# MSP430FR2355 register map
Vendor: msp430gen; File version: v0.4.0-28-gb0087ce-dirty
Registers are 16-bit, read-write, reset 0x0 unless marked. A register's access mark holds for its fields unless they carry their own. Offsets are from the block's base; [hi:lo] are bit positions; {n}, {i} and the like mark numbered series; 'fields as' and 'values as' point back to an identical list.

## RTC
Base 0x00000300
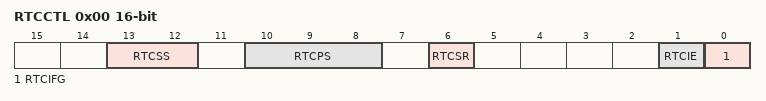
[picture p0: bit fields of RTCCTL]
0x00 RTCCTL — RTCCTL0 Register
  [13:12] RTCSS — Real-time clock source select
    0=DISABLED; 1=SMCLK; 2=XT1CLK; 3=VLOCLK
  [10:8] RTCPS — Real-time clock pre-divider select
    0=1; 1=10; 2=100; 3=1000; 4=16; 5=64; 6=256; 7=1024
  [6] RTCSR — Real-time software reset. This is a write only bit and is always read with logic 0. 0b = Write 0 has no effect
    0=Write 0 has no effect; 1=Write 1 to this bit clears the counter value and reloads the shadow register value from the modulo register at the next tick of the selected source clock. No overflow event or interrupt is generated.
  [1] RTCIE — Real-time interrupt enable
    0=Interrupt disabled; 1=Interrupt enabled
  [0] RTCIFG ro — Real-time interrupt flag. This bit reports the status of a pending interrupt. This read only bit can be cleared by reading RTCIV register.
    0=No interrupt pending; 1=Interrupt pending
0x04 RTCIV — Real-Time Clock Interrupt Vector Register
  [15:0] RTCIV ro — Real-time clock interrupt vector value
    0=NONE (No interrupt pending); 2=RTCIFG (upt Source: RTC Counter Overflow; Interrupt Flag: RTCIFG)
0x08 RTCMOD — RTC Counter Modulo Register
0x0C RTCCNT — RTC Counter Register

## MPY32
Base 0x000004C0
0x00 MPY — 16-bit operand one multiply
0x02 MPYS — 16-bit operand one signed multiply
0x04 MAC — 16-bit operand one multiply accumulate
0x06 MACS — 16-bit operand one signed multiply accumulate
0x08 OP2 — 16-bit operand two
0x0A RESLO — 16x16-bit result low word
0x0C RESHI — 16x16-bit result high word
0x0E SUMEXT — 16x16-bit sum extension register
0x10 MPY32L — 32-bit operand 1 multiply low word
0x12 MPY32H — 32-bit operand 1 multiply high word
0x14 MPYS32L — 32-bit operand 1 signed multiply low word
0x16 MPYS32H — 32-bit operand 1 signed multiply high word
0x18 MAC32L — 32-bit operand 1 multiply accumulate low word
0x1A MAC32H — 32-bit operand 1 multiply accumulate high word
0x1C MACS32L — 32-bit operand 1 signed multiply accumulate low word
0x1E MACS32H — 32-bit operand 1 signed multiply accumulate high word
0x20 OP2L — 32-bit operand 2 low word
0x22 OP2H — 32-bit operand 2 high word
0x24 RES0 — 32x32-bit result 0 least significant word
0x26 RES1 — 32x32-bit result 1
0x28 RES2 — 32x32-bit result 2
0x2A RES3 — 32x32-bit result 3 most significant word
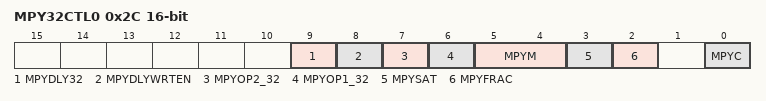
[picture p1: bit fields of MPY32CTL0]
0x2C MPY32CTL0 — MPY32 control register 0
  [9] MPYDLY32 — Delayed write mode.
    0=Writes are delayed until 64-bit result (RES0 to RES3) is available; 1=Writes are delayed until 32-bit result (RES0 to RES1) is available. 8 MPYDLYWRTEN
  [8] MPYDLYWRTEN — Delayed write enable.
    0=Writes are not delayed; 1=Writes are delayed
  [7] MPYOP2_32 — Multiplier bit width of operand 2
    0=16 bits; 1=32 bits
  [6] MPYOP1_32 — Multiplier bit width of operand 1
    0=16 bits; 1=32 bits
  [5:4] MPYM — Multiplier mode
    0=MPY (MPY Multiply); 1=MPYS (MPYS Signed multiply); 2=MAC (MAC Multiply accumulate); 3=MACS (MACS Signed multiply accumulate)
  [3] MPYSAT — Saturation mode
    0=DISABLE (Saturation mode disabled.); 1=ENABLE (Saturation mode enabled.)
  [2] MPYFRAC — Fractional mode.
    0=DISABLE (Fractional mode disabled.); 1=ENABLE (Fractional mode enabled.)
  [0] MPYC — Carry of the multiplier
    0=No carry for result; 1=Result has a carry

## BAKMEM
Base 0x00000660
0x00 BAKMEM0 — Backup Memory registers. Backup Memory 0.
{0x0+2i} BAKMEM{i} (i=1..9) — Backup Memory {i}.
0x14 BAKMEM10 — Backup Memory registers. Backup Memory 10.
{0x0+2i} BAKMEM{i} (i=11..15) — Backup Memory {i}.

## ICC
Base 0x000006C0
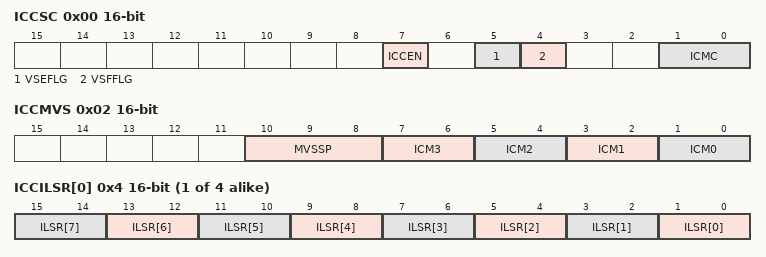
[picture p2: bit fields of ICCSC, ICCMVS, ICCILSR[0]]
0x00 ICCSC
  [7] ICCEN — ICC enable
    0=ICC module disabled; 1=ICC module enabled
  [5] VSEFLG ro — Virtual stack empty flag.This bit indicates whether or not the virtual stack is empty. It is automatically updated when the stack is pushed or popped.
    0=Stack has valid data; 1=Stack has no valid data
  [4] VSFFLG ro — Virtual stack full flag This bit indicates whether or not the virtual stack is full. It is automatically updated when the stack is pushed or popped.
    0=ICCMVS register is not full; 1=ICCMVS register is full
  [1:0] ICMC ro — Current Interrupt Compare Mask of virtual stack specifies the current ICM at the top of virtual stack If ICM[1:0] is less than the priority level (ILSRx[1:0]) of the new interrupt, the corresponding source is sent to the CPU. Note that the ICMC is the element stack that the stack pointer is pointing to.
    0=HIGHEST (Level 0, the highest priority); 1=HIGH (Level 1); 2=LOW (Level 2); 3=LOWEST (Level 3, the lowest priority)
0x02 ICCMVS
  [10:8] MVSSP ro — MVS stack pointer indicate register
    0=000b = Stack empty; 1=001b = ICM0 affected; 2=010b = ICM0 and ICM1 affected; 3=011b = ICM0, ICM1, and ICM2 affected; 4=100b = ICM0, ICM1, ICM2, and ICM3 affected. Also means the stack is full.
  [2n+1:2n] ICM{n} ro (n=0..3) — Interrupt compare mask virtual stack position {n} This field is the virtual stack register for ICM{n}.
{0x4+2i} ICCILSR[{i}] (i=0..3) — Interrupt Compare Controller Interrupt Level Setting Register
  [2n+1:2n] ILSR[{n}] (n=0..7) — Interrupt level of interrupt source 8 x (register index) + (field index)
    values as ICCSC.ICMC
